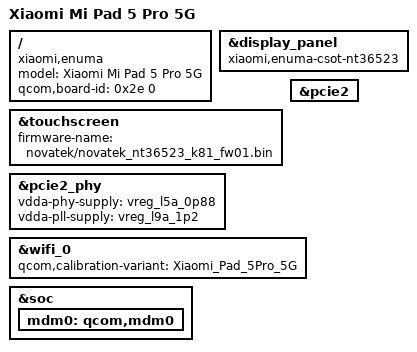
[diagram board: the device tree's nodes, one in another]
// SPDX-License-Identifier: BSD-3-Clause
/*
 * Copyright (c) 2025 Dawid Wróbel <me@dawidwrobel.com>
 */

/dts-v1/;

#include "sm8250-xiaomi-elish-common.dtsi"

/ {
	model = "Xiaomi Mi Pad 5 Pro 5G";
	compatible = "xiaomi,enuma", "xiaomi,elish", "qcom,sm8250";

	/* Platform type differs from elish; msm-id is inherited unchanged. */
	qcom,board-id = <0x2e 0>;
};

&display_panel {
	compatible = "xiaomi,enuma-csot-nt36523", "xiaomi,elish-csot-nt36523", "novatek,nt36523";
	status = "okay";
};

&touchscreen {
	firmware-name = "novatek/novatek_nt36523_k81_fw01.bin";
	status = "okay";
};

&pcie2 {
	status = "okay";
};

&pcie2_phy {
	vdda-phy-supply = <&vreg_l5a_0p88>;
	vdda-pll-supply = <&vreg_l9a_1p2>;
	status = "okay";
};

&wifi_0 {
	qcom,calibration-variant = "Xiaomi_Pad_5Pro_5G";
};

&soc {
	mdm0: qcom,mdm0 {
		status = "okay";
	};
};
